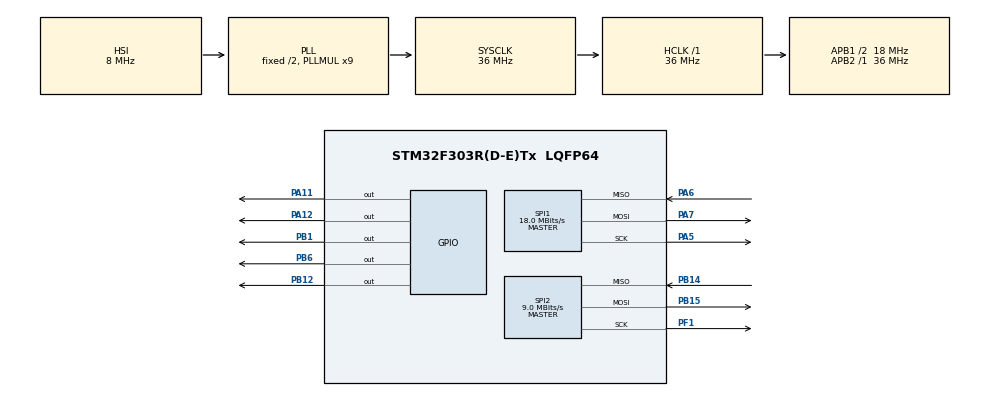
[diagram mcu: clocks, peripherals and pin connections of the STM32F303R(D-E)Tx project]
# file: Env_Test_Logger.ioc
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Mcu.Family=STM32F3
Mcu.Name=STM32F303R(D-E)Tx
Mcu.Package=LQFP64
NVIC.PriorityGroup=NVIC_PRIORITYGROUP_0
PA11.Signal=GPIO_Output
PA12.Signal=GPIO_Output
PA13.Mode=Serial_Wire
PA13.Signal=SYS_JTMS-SWDIO
PA14.Mode=Serial_Wire
PA14.Signal=SYS_JTCK-SWCLK
PA5.Mode=Full_Duplex_Master
PA5.Signal=SPI1_SCK
PA6.Mode=Full_Duplex_Master
PA6.Signal=SPI1_MISO
PA7.Mode=Full_Duplex_Master
PA7.Signal=SPI1_MOSI
PB1.Signal=GPIO_Output
PB12.Signal=GPIO_Output
PB14.Mode=Full_Duplex_Master
PB14.Signal=SPI2_MISO
PB15.Mode=Full_Duplex_Master
PB15.Signal=SPI2_MOSI
PB6.Signal=GPIO_Output
PC14-OSC32_IN.Mode=LSE-External-Oscillator
PC14-OSC32_IN.Signal=RCC_OSC32_IN
PC15-OSC32_OUT.Mode=LSE-External-Oscillator
PC15-OSC32_OUT.Signal=RCC_OSC32_OUT
PF0-OSC_IN.Mode=HSE-External-Clock-Source
PF0-OSC_IN.Signal=RCC_OSC_IN
PF1-OSC_OUT.Mode=Full_Duplex_Master
PF1-OSC_OUT.Signal=SPI2_SCK
ProjectManager.HeapSize=0x200
ProjectManager.StackSize=0x400
ProjectManager.TargetToolchain=STM32CubeIDE
RCC.AHBFreq_Value=36000000
RCC.APB1CLKDivider=RCC_HCLK_DIV2
RCC.APB1Freq_Value=18000000
RCC.APB1TimFreq_Value=36000000
RCC.APB2Freq_Value=36000000
RCC.APB2TimFreq_Value=36000000
RCC.CortexFreq_Value=36000000
RCC.HCLKFreq_Value=36000000
RCC.HSE_VALUE=8000000
RCC.HSI_VALUE=8000000
RCC.PLLM=8
RCC.PLLMUL=RCC_PLL_MUL9
RCC.PLLN=336
RCC.PLLP=RCC_PLLP_DIV4
RCC.PLLQ=7
RCC.RCC_PLLsource_Clock_Source_FROM_HSE=RCC_HSE_PREDIV_DIV2
RCC.SYSCLKFreq_VALUE=36000000
RCC.SYSCLKSourceVirtual=RCC_SYSCLKSOURCE_PLLCLK
RCC.USBFreq_Value=36000000
SPI1.CalculateBaudRate=18.0 MBits/s
SPI1.Direction=SPI_DIRECTION_2LINES
SPI1.Mode=SPI_MODE_MASTER
SPI1.VirtualType=VM_MASTER
SPI2.CalculateBaudRate=9.0 MBits/s
SPI2.Direction=SPI_DIRECTION_2LINES
SPI2.Mode=SPI_MODE_MASTER
SPI2.VirtualType=VM_MASTER
VP_FATFS_VS_Generic.Mode=User_defined
board=NUCLEO-F303RE

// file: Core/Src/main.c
/* USER CODE BEGIN Header */
/**
  ******************************************************************************
  * @file           : main.c
  * @brief          : Main program body
  ******************************************************************************
  * @attention
  *
  * Copyright (c) 2026 STMicroelectronics.
  * All rights reserved.
  *
  * This software is licensed under terms that can be found in the LICENSE file
  * in the root directory of this software component.
  * If no LICENSE file comes with this software, it is provided AS-IS.
  *
  ******************************************************************************
  */
/* USER CODE END Header */
#include "main.h"
#include "fatfs.h"

/* USER CODE BEGIN Includes */
#include <String.h>
/* USER CODE END Includes */

SPI_HandleTypeDef hspi1;
SPI_HandleTypeDef hspi2;

void SystemClock_Config(void);
static void MX_GPIO_Init(void);
static void MX_SPI1_Init(void);
static void MX_SPI2_Init(void);

int main(void)
{

  /* System Init -------------------------------------------------------------*/

  HAL_Init();  // Reset of all peripherals, Initializes the Flash interface and the Systick.

  SystemClock_Config();  // Configure the system clock

  /* Initialize all configured peripheral interfaces */
  MX_GPIO_Init();  // GPIO: Status LED and CS pins
  MX_SPI1_Init();  // SPI1: MicroSD Card slot
  MX_SPI2_Init();  // SPI2: Sensor ICs

  /* Storage Init ------------------------------------------------------------*/

  sys_status_t storage = storage_init();  // Attempt to initialize storage

  if (storage != OK) {
	  sys_status_t fallback = storage_error(MAX_RETRIES);  // Enter retry loop upon initial failure

	  if (fallback != OK) {
		  Error_Handler();    // Halt system after max retires
	  }
  }

  /* Sensor Init -------------------------------------------------------------*/

  sys_status_t sensor = sensor_init();  // Attempt to initialize sensors

  if (sensor != OK) {
	  Error_Handler();    // Halt system
  }

  /* Init Logic Complete -----------------------------------------------------*/

  /* Infinite loop */
  while (1)
  {
	/* USER CODE END WHILE */

	/* USER CODE BEGIN 3 */
  }

  /* Finalize Log ------------------------------------------------------------*/
}

void SystemClock_Config(void)
{
  RCC_OscInitTypeDef RCC_OscInitStruct = {0};
  RCC_ClkInitTypeDef RCC_ClkInitStruct = {0};

  /** Initializes the RCC Oscillators according to the specified parameters
  * in the RCC_OscInitTypeDef structure.
  */
  RCC_OscInitStruct.OscillatorType = RCC_OSCILLATORTYPE_HSI;
  RCC_OscInitStruct.HSIState = RCC_HSI_ON;
  RCC_OscInitStruct.HSICalibrationValue = RCC_HSICALIBRATION_DEFAULT;
  RCC_OscInitStruct.PLL.PLLState = RCC_PLL_ON;
  RCC_OscInitStruct.PLL.PLLSource = RCC_PLLSOURCE_HSI;
  RCC_OscInitStruct.PLL.PLLMUL = RCC_PLL_MUL9;
  RCC_OscInitStruct.PLL.PREDIV = RCC_PREDIV_DIV1;
  if (HAL_RCC_OscConfig(&RCC_OscInitStruct) != HAL_OK)
  {
    Error_Handler();
  }

  /** Initializes the CPU, AHB and APB buses clocks
  */
  RCC_ClkInitStruct.ClockType = RCC_CLOCKTYPE_HCLK|RCC_CLOCKTYPE_SYSCLK
                              |RCC_CLOCKTYPE_PCLK1|RCC_CLOCKTYPE_PCLK2;
  RCC_ClkInitStruct.SYSCLKSource = RCC_SYSCLKSOURCE_PLLCLK;
  RCC_ClkInitStruct.AHBCLKDivider = RCC_SYSCLK_DIV1;
  RCC_ClkInitStruct.APB1CLKDivider = RCC_HCLK_DIV2;
  RCC_ClkInitStruct.APB2CLKDivider = RCC_HCLK_DIV1;

  if (HAL_RCC_ClockConfig(&RCC_ClkInitStruct, FLASH_LATENCY_1) != HAL_OK)
  {
    Error_Handler();
  }
}

static void MX_SPI1_Init(void)
{

  /* SPI1 parameter configuration*/
  hspi1.Instance = SPI1;
  hspi1.Init.Mode = SPI_MODE_MASTER;
  hspi1.Init.Direction = SPI_DIRECTION_2LINES;
  hspi1.Init.DataSize = SPI_DATASIZE_4BIT;
  hspi1.Init.CLKPolarity = SPI_POLARITY_LOW;
  hspi1.Init.CLKPhase = SPI_PHASE_1EDGE;
  hspi1.Init.NSS = SPI_NSS_SOFT;
  hspi1.Init.BaudRatePrescaler = SPI_BAUDRATEPRESCALER_2;
  hspi1.Init.FirstBit = SPI_FIRSTBIT_MSB;
  hspi1.Init.TIMode = SPI_TIMODE_DISABLE;
  hspi1.Init.CRCCalculation = SPI_CRCCALCULATION_DISABLE;
  hspi1.Init.CRCPolynomial = 7;
  hspi1.Init.CRCLength = SPI_CRC_LENGTH_DATASIZE;
  hspi1.Init.NSSPMode = SPI_NSS_PULSE_ENABLE;
  if (HAL_SPI_Init(&hspi1) != HAL_OK)
  {
    Error_Handler();
  }

}

static void MX_SPI2_Init(void)
{

  /* SPI2 parameter configuration*/
  hspi2.Instance = SPI2;
  hspi2.Init.Mode = SPI_MODE_MASTER;
  hspi2.Init.Direction = SPI_DIRECTION_2LINES;
  hspi2.Init.DataSize = SPI_DATASIZE_4BIT;
  hspi2.Init.CLKPolarity = SPI_POLARITY_LOW;
  hspi2.Init.CLKPhase = SPI_PHASE_1EDGE;
  hspi2.Init.NSS = SPI_NSS_SOFT;
  hspi2.Init.BaudRatePrescaler = SPI_BAUDRATEPRESCALER_2;
  hspi2.Init.FirstBit = SPI_FIRSTBIT_MSB;
  hspi2.Init.TIMode = SPI_TIMODE_DISABLE;
  hspi2.Init.CRCCalculation = SPI_CRCCALCULATION_DISABLE;
  hspi2.Init.CRCPolynomial = 7;
  hspi2.Init.CRCLength = SPI_CRC_LENGTH_DATASIZE;
  hspi2.Init.NSSPMode = SPI_NSS_PULSE_ENABLE;
  if (HAL_SPI_Init(&hspi2) != HAL_OK)
  {
    Error_Handler();
  }

}

static void MX_GPIO_Init(void)
{
  GPIO_InitTypeDef GPIO_InitStruct = {0};

  /* GPIO Ports Clock Enable */
  __HAL_RCC_GPIOC_CLK_ENABLE();
  __HAL_RCC_GPIOF_CLK_ENABLE();
  __HAL_RCC_GPIOA_CLK_ENABLE();
  __HAL_RCC_GPIOB_CLK_ENABLE();

  /*Configure GPIO pin Output Level */
  HAL_GPIO_WritePin(GPIOB, GPIO_PIN_1|GPIO_PIN_12|GPIO_PIN_6, GPIO_PIN_RESET);

  /*Configure GPIO pin Output Level */
  HAL_GPIO_WritePin(GPIOA, GPIO_PIN_11|GPIO_PIN_12, GPIO_PIN_RESET);

  /*Configure GPIO pins : PB1 PB12 PB6 */
  GPIO_InitStruct.Pin = GPIO_PIN_1|GPIO_PIN_12|GPIO_PIN_6;
  GPIO_InitStruct.Mode = GPIO_MODE_OUTPUT_PP;
  GPIO_InitStruct.Pull = GPIO_NOPULL;
  GPIO_InitStruct.Speed = GPIO_SPEED_FREQ_LOW;
  HAL_GPIO_Init(GPIOB, &GPIO_InitStruct);

  /*Configure GPIO pins : PA11 PA12 */
  GPIO_InitStruct.Pin = GPIO_PIN_11|GPIO_PIN_12;
  GPIO_InitStruct.Mode = GPIO_MODE_OUTPUT_PP;
  GPIO_InitStruct.Pull = GPIO_NOPULL;
  GPIO_InitStruct.Speed = GPIO_SPEED_FREQ_LOW;
  HAL_GPIO_Init(GPIOA, &GPIO_InitStruct);

}

/* USER CODE BEGIN 4 */
sys_status_t storage_init(){
	return ERR;
}

sys_status_t sensor_init() {
	return ERR;
}

sys_status_t storage_error(int max_retries) {
	return ERR;
}
/* USER CODE END 4 */

void Error_Handler(void)
{
  /* USER CODE BEGIN Error_Handler_Debug */
  /* User can add his own implementation to report the HAL error return state */
  __disable_irq();
  while (1)
  {
	  HAL_GPIO_TogglePin(STATUS_LED_PORT, STATUS_LED_PIN);

	  // Make the LED blink, HAL_DELAY() was just disabled by __disable_irq();
	  for (volatile uint32_t i = 0; i < 2500000; i++)
	  {
		  __NOP();
	  }
  }
  /* USER CODE END Error_Handler_Debug */
}
